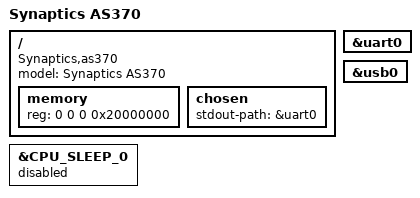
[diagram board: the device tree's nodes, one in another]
/* SPDX-License-Identifier: GPL-2.0+ */
/*
 * Copyright (C) 2019 Synaptics Incorporated
 *
 * Author:
 * Cheng Lu <Cheng.Lu@synaptics.com>
 */

/dts-v1/;

#include <dt-bindings/gpio/gpio.h>

#include "as370.dtsi"

/ {
	model = "Synaptics AS370";
	compatible = "Synaptics,as370", "Synaptics,asserial";

	memory {
		device_type = "memory";
		reg = <0 0 0 0x20000000>;
	};

	chosen {
                stdout-path = &uart0;
        };

};

&CPU_SLEEP_0 {
	status = "disabled";
};

&uart0 {
	status = "okay";
};

&usb0 {
	status = "okay";
};
